AUTOSAR XML (schema 4-2-2)
package /EB/SoftwareComponents
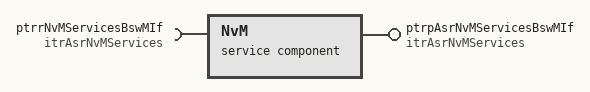
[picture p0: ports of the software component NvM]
  service sw component type NvM: category=ASR_Interfaces
    provide port ptrpAsrNvMServicesBswMIf: provided-interface=itrAsrNvMServices
    require port ptrrNvMServicesBswMIf: required-interface=itrAsrNvMServices
    behavior NvM_IB: handle-termination-and-restart=NO-SUPPORT
      4 x runnable:
        NvM_Init
        NvM_MainFunction
        NvM_ReadAll
        NvM_WriteAll
package /EB/TriggerInterfaces
  trigger interface itrAsrNvMServices
    5 x trigger, all with trigger-period={cse-code=1000, cse-code-factor=0}:
      BswM_CB_NfyNvMJobEnd
      NvM_Init
      NvM_MainFunction
      NvM_ReadAll
      NvM_WriteAll
